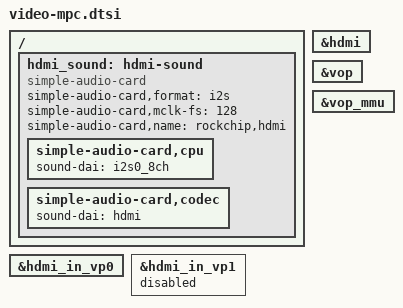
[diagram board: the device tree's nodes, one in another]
/ {
	hdmi_sound: hdmi-sound {
		compatible = "simple-audio-card";
		simple-audio-card,format = "i2s";
		simple-audio-card,mclk-fs = <128>;
		simple-audio-card,name = "rockchip,hdmi";
		status = "disabled";

		simple-audio-card,cpu {
				sound-dai = <&i2s0_8ch>;
		};
		simple-audio-card,codec {
				sound-dai = <&hdmi>;
		};
	};
};


&hdmi_sound {
	status = "okay";
};

&hdmi {
	status = "okay";
};

&hdmi_in_vp0 {
	status = "okay";
};

&hdmi_in_vp1 {
	status = "disabled";
};

&hdmi_sound {
	status = "okay";
};

&vop {
	status = "okay";
};

&vop_mmu {
	status = "okay";
};
